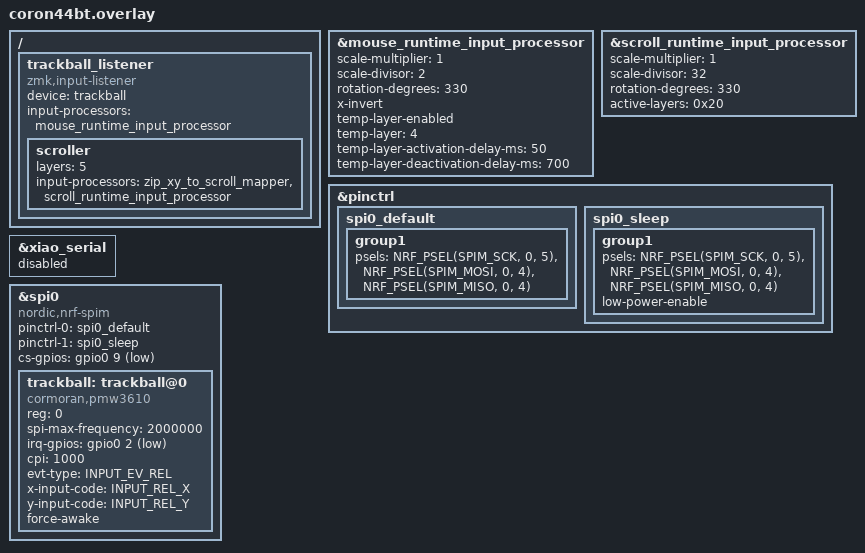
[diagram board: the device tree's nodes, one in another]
#include "coron44bt.dtsi"
#include <input/processors.dtsi>
#include <input/processors/runtime-input-processor.dtsi>

&mouse_runtime_input_processor {
    scale-multiplier = <1>;
    scale-divisor = <2>;
    rotation-degrees = <330>;
    x-invert;
    temp-layer-enabled;
    temp-layer = <4>;
    temp-layer-activation-delay-ms = <50>;
    temp-layer-deactivation-delay-ms = <700>;
};

&scroll_runtime_input_processor {
    scale-multiplier = <1>;
    scale-divisor = <32>;
    rotation-degrees = <330>;
    active-layers = <0x20>;
};

/ {
    trackball_listener: trackball_listener {
        compatible = "zmk,input-listener";
        device = <&trackball>;
        input-processors = <&mouse_runtime_input_processor>;

        scroller {
            layers = <5>;
            input-processors = <&zip_xy_to_scroll_mapper &scroll_runtime_input_processor>;
        };
    };
};

&pinctrl {
    spi0_default: spi0_default {
        group1 {
            psels = <NRF_PSEL(SPIM_SCK, 0, 5)>,
                <NRF_PSEL(SPIM_MOSI, 0, 4)>,
                <NRF_PSEL(SPIM_MISO, 0, 4)>;
        };
    };

    spi0_sleep: spi0_sleep {
        group1 {
            psels = <NRF_PSEL(SPIM_SCK, 0, 5)>,
                <NRF_PSEL(SPIM_MOSI, 0, 4)>,
                <NRF_PSEL(SPIM_MISO, 0, 4)>;
            low-power-enable;
        };
    };
};

&xiao_serial { status = "disabled"; };

&spi0 {
    status = "okay";
    compatible = "nordic,nrf-spim";
    pinctrl-0 = <&spi0_default>;
    pinctrl-1 = <&spi0_sleep>;
    pinctrl-names = "default", "sleep";
    cs-gpios = <&gpio0 9 GPIO_ACTIVE_LOW>;

    trackball: trackball@0 {
        status = "okay";
        compatible = "cormoran,pmw3610";
        reg = <0>;
        spi-max-frequency = <2000000>;
        irq-gpios = <&gpio0 2 (GPIO_ACTIVE_LOW | GPIO_PULL_UP)>;
        cpi = <1000>;
        evt-type = <INPUT_EV_REL>;
        x-input-code = <INPUT_REL_X>;
        y-input-code = <INPUT_REL_Y>;
        force-awake;
    };
};


